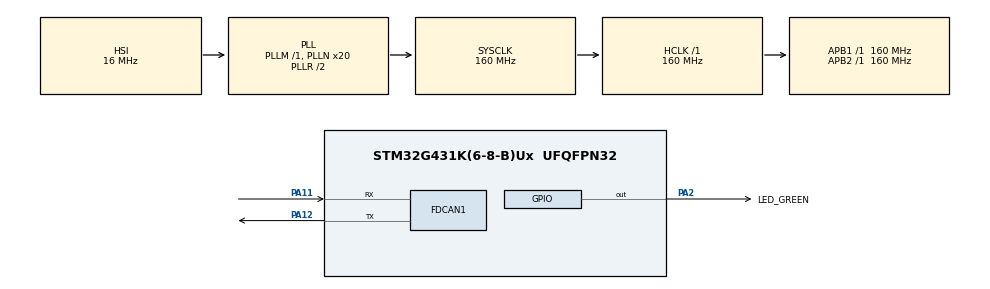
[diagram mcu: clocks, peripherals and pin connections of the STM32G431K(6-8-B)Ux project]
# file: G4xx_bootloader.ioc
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FDCAN1.CalculateBaudRateNominal=1000000
FDCAN1.CalculateTimeBitNominal=1000
FDCAN1.CalculateTimeQuantumNominal=50.0
FDCAN1.DataPrescaler=4
FDCAN1.DataSyncJumpWidth=2
FDCAN1.DataTimeSeg1=5
FDCAN1.DataTimeSeg2=2
FDCAN1.FrameFormat=FDCAN_FRAME_FD_BRS
FDCAN1.NominalPrescaler=8
FDCAN1.NominalSyncJumpWidth=4
FDCAN1.NominalTimeSeg1=15
FDCAN1.NominalTimeSeg2=4
FDCAN1.StdFiltersNbr=1
Mcu.Family=STM32G4
Mcu.Name=STM32G431K(6-8-B)Ux
Mcu.Package=UFQFPN32
NVIC.FDCAN1_IT0_IRQn=true\:5\:0\:true\:false\:true\:true\:true\:true
NVIC.FDCAN1_IT1_IRQn=true\:5\:0\:true\:false\:true\:true\:true\:true
NVIC.PriorityGroup=NVIC_PRIORITYGROUP_4
NVIC.TIM7_IRQn=true\:6\:0\:true\:false\:true\:true\:true\:true
PA11.Mode=FDCAN_Activate
PA11.Signal=FDCAN1_RX
PA12.Mode=FDCAN_Activate
PA12.Signal=FDCAN1_TX
PA13.Mode=Serial_Wire
PA13.Signal=SYS_JTMS-SWDIO
PA14.Mode=Serial_Wire
PA14.Signal=SYS_JTCK-SWCLK
PA2.GPIO_Label=LED_GREEN
PA2.Signal=GPIO_Output
ProjectManager.HeapSize=0x200
ProjectManager.StackSize=0x400
ProjectManager.TargetToolchain=STM32CubeIDE
RCC.ADC12Freq_Value=160000000
RCC.AHBFreq_Value=160000000
RCC.APB1Freq_Value=160000000
RCC.APB1TimFreq_Value=160000000
RCC.APB2Freq_Value=160000000
RCC.APB2TimFreq_Value=160000000
RCC.CK48CLockSelection=RCC_USBCLKSOURCE_HSI48
RCC.CortexFreq_Value=160000000
RCC.EXTERNAL_CLOCK_VALUE=12288000
RCC.HCLKFreq_Value=160000000
RCC.HSE_VALUE=8000000
RCC.HSI48_VALUE=48000000
RCC.HSI_VALUE=16000000
RCC.LSE_VALUE=32768
RCC.PLLN=20
RCC.SYSCLKFreq_VALUE=160000000
RCC.SYSCLKSource=RCC_SYSCLKSOURCE_PLLCLK
RCC.USBFreq_Value=48000000
RCC.VCOOutputFreq_Value=320000000
TIM7.PeriodNoDither=1000
TIM7.Prescaler=160-1
VP_SYS_VS_DBSignals.Mode=DisableDeadBatterySignals
VP_TIM7_VS_ClockSourceINT.Mode=Enable_Timer
board=custom

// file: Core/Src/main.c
/* USER CODE BEGIN Header */
/**
  ******************************************************************************
  * @file           : main.c
  * @brief          : Main program body
  ******************************************************************************
  * @attention
  *
  * Copyright (c) 2025 STMicroelectronics.
  * All rights reserved.
  *
  * This software is licensed under terms that can be found in the LICENSE file
  * in the root directory of this software component.
  * If no LICENSE file comes with this software, it is provided AS-IS.
  *
  ******************************************************************************
  */
/* USER CODE END Header */
#include "main.h"
#include "fdcan.h"
#include "tim.h"
#include "gpio.h"

void SystemClock_Config(void);

int main(void)
{

  /* MCU Configuration--------------------------------------------------------*/

  /* Reset of all peripherals, Initializes the Flash interface and the Systick. */
  HAL_Init();

  /* Configure the system clock */
  SystemClock_Config();

  /* Initialize all configured peripherals */
  MX_GPIO_Init();
  MX_FDCAN1_Init();
  MX_TIM7_Init();
  /* USER CODE BEGIN 2 */
  HAL_TIM_Base_Start_IT(&htim7);
  bsp_InitTimer();
  CAN_bsp_init();

  /* USER CODE END 2 */

  /* Infinite loop */
  while (1)
  {

    /* USER CODE BEGIN 3 */
    Bootloader_Excute();
  }
  /* USER CODE END 3 */
}

void SystemClock_Config(void)
{
  RCC_OscInitTypeDef RCC_OscInitStruct = {0};
  RCC_ClkInitTypeDef RCC_ClkInitStruct = {0};

  /** Configure the main internal regulator output voltage
  */
  HAL_PWREx_ControlVoltageScaling(PWR_REGULATOR_VOLTAGE_SCALE1_BOOST);

  /** Initializes the RCC Oscillators according to the specified parameters
  * in the RCC_OscInitTypeDef structure.
  */
  RCC_OscInitStruct.OscillatorType = RCC_OSCILLATORTYPE_HSI;
  RCC_OscInitStruct.HSIState = RCC_HSI_ON;
  RCC_OscInitStruct.HSICalibrationValue = RCC_HSICALIBRATION_DEFAULT;
  RCC_OscInitStruct.PLL.PLLState = RCC_PLL_ON;
  RCC_OscInitStruct.PLL.PLLSource = RCC_PLLSOURCE_HSI;
  RCC_OscInitStruct.PLL.PLLM = RCC_PLLM_DIV1;
  RCC_OscInitStruct.PLL.PLLN = 20;
  RCC_OscInitStruct.PLL.PLLP = RCC_PLLP_DIV2;
  RCC_OscInitStruct.PLL.PLLQ = RCC_PLLQ_DIV2;
  RCC_OscInitStruct.PLL.PLLR = RCC_PLLR_DIV2;
  if (HAL_RCC_OscConfig(&RCC_OscInitStruct) != HAL_OK)
  {
    Error_Handler();
  }

  /** Initializes the CPU, AHB and APB buses clocks
  */
  RCC_ClkInitStruct.ClockType = RCC_CLOCKTYPE_HCLK|RCC_CLOCKTYPE_SYSCLK
                              |RCC_CLOCKTYPE_PCLK1|RCC_CLOCKTYPE_PCLK2;
  RCC_ClkInitStruct.SYSCLKSource = RCC_SYSCLKSOURCE_PLLCLK;
  RCC_ClkInitStruct.AHBCLKDivider = RCC_SYSCLK_DIV1;
  RCC_ClkInitStruct.APB1CLKDivider = RCC_HCLK_DIV1;
  RCC_ClkInitStruct.APB2CLKDivider = RCC_HCLK_DIV1;

  if (HAL_RCC_ClockConfig(&RCC_ClkInitStruct, FLASH_LATENCY_4) != HAL_OK)
  {
    Error_Handler();
  }
}

void Error_Handler(void)
{
  __disable_irq();
  while (1)
  {
  }
}
